# AT32UC3C2128C device description
Architecture: AVR32_UC3; Family: AVR UC3
Registers are 32-bit, read-write, reset 0x0 unless marked. A register's access mark holds for its fields unless they carry their own. Offsets are from the block's base; [hi:lo] are bit positions; lines under a group give offsets from that group; {n}, {i} and the like mark numbered series; 'fields as' and 'values as' point back to an identical list.

## PWM — Pulse Width Modulation Controller
Instances: PWM 0xffff4c00
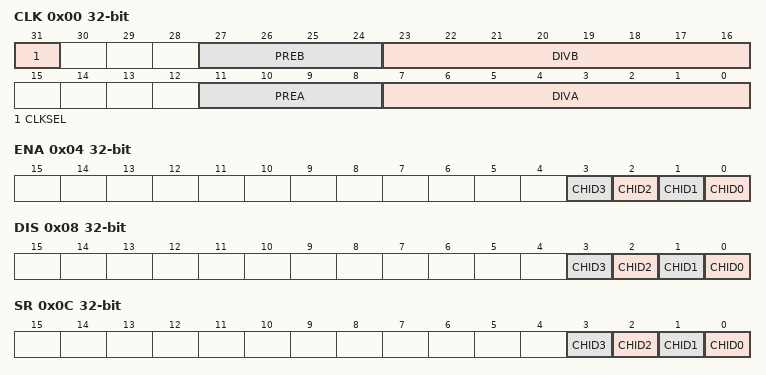
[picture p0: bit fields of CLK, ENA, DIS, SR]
0x00 CLK — PWM Clock Register
  [31] CLKSEL — Clock select
  [27:24] PREB
    0=CCK; 1=CCK_DIV_2; 2=CCK_DIV_4; 3=CCK_DIV_8; 4=CCK_DIV_16; 5=CCK_DIV_32; 6=CCK_DIV_64; 7=CCK_DIV_128; 8=CCK_DIV_256; 9=CCK_DIV_512; 10=CCK_DIV_1024
  [23:16] DIVB — CLKB divide factor
    0=CLK_OFF; 1=CLK_SEL_PREB
  [11:8] PREA
    values as PREB
  [7:0] DIVA — CLKA divide factor
    0=CLK_OFF; 1=CLK_SEL_PREA
0x04 ENA wo reset not defined — PWM Enable Register
  [n] CHID{n} (n=0..3) — Channel ID {n}
0x08 DIS wo reset not defined — PWM Disable Register
  [n] CHID{n} (n=0..3) — Channel ID {n}
0x0C SR ro — PWM Status Register
  [n] CHID{n} (n=0..3) — Channel ID {n}
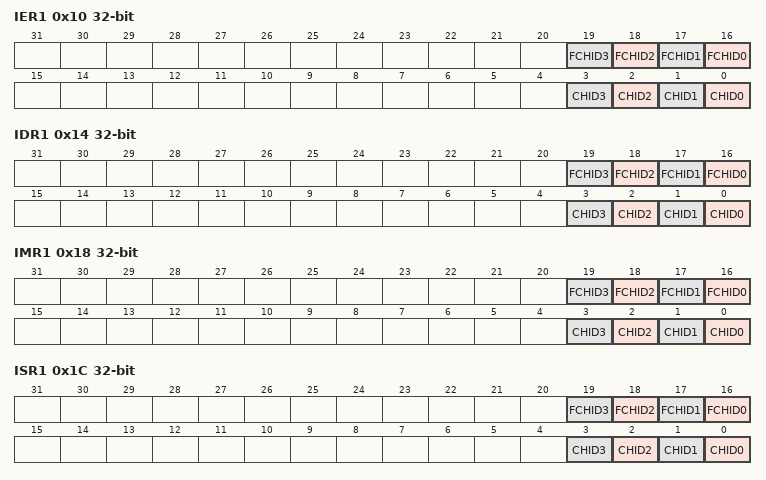
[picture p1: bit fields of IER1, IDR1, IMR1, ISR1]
0x10 IER1 wo reset not defined — PWM Interrupt Enable Register 1
  [n+16] FCHID{n} (n=0..3) — Fault Event on Channel {n} Interrupt Enable
  [n] CHID{n} (n=0..3) — Counter Event on Channel {n} Interrupt Enable
0x14 IDR1 wo reset not defined — PWM Interrupt Disable Register 1
  [n+16] FCHID{n} (n=0..3) — Fault Event on Channel {n} Interrupt Disable
  [n] CHID{n} (n=0..3) — Counter Event on Channel {n} Interrupt Disable
0x18 IMR1 ro — PWM Interrupt Mask Register 1
  [n+16] FCHID{n} (n=0..3) — Fault Event on Channel {n} Interrupt Mask
  [n] CHID{n} (n=0..3) — Counter Event on Channel {n} Interrupt Mask
0x1C ISR1 ro — PWM Interrupt Status Register 1
  [n+16] FCHID{n} (n=0..3) — Fault Event on Channel {n}
  [n] CHID{n} (n=0..3) — Counter Event on Channel {n}
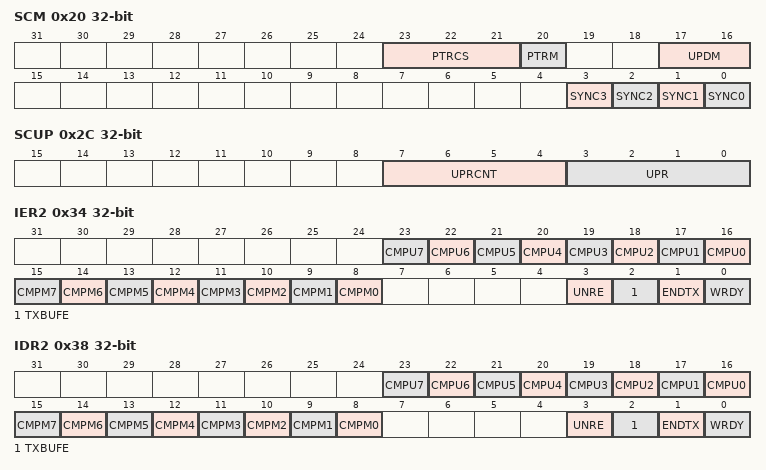
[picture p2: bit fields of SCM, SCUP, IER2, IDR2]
0x20 SCM — PWM Synch Channels Mode Register
  [23:21] PTRCS — PDC Transfer Request Comparison Selection
  [20] PTRM — PDC Transfer Request Mode
    0=PER; 1=CMP
  [17:16] UPDM — Synchronized Channels Update Mode
  [n] SYNC{n} (n=0..3) — Synchronized channel {n}
0x24 PDCDATA
0x28 SCUC — PWM Sync Channels Update Control Register
  [0] UPDULOCK — Synchronous Channels Update Unlock
0x2C SCUP — PWM Sync Channels Update Period Value Register
  [7:4] UPRCNT — Update Period Counter
  [3:0] UPR — Update Period
0x30 SCUPUPD wo — PWM Sync Channels Update Period Value Update Register
  [15:0] UPRUPD — Update Period Update
0x34 IER2 wo reset not defined — PWM Interrupt Enable Register 2
  [n+16] CMPU{n} (n=0..7) — Comparison {n} Update Interrupt Enable
  [n+8] CMPM{n} (n=0..7) — Comparison {n} Match Interrupt Enable
  [3] UNRE — Synchronous Channels Update Underrun Error Interrupt Enable
  [2] TXBUFE — PDC TX Buffer Empty Interrupt Enable
  [1] ENDTX — PDC End of TX Buffer Interrupt Enable
  [0] WRDY — Write Ready for Synchronous Channels Update Interrupt Enable
0x38 IDR2 wo reset not defined — PWM Interrupt Disable Register 2
  [n+16] CMPU{n} (n=0..7) — Comparison {n} Update Interrupt Disable
  [n+8] CMPM{n} (n=0..7) — Comparison {n} Match Interrupt Disable
  [3] UNRE — Synchronous Channels Update Underrun Error Interrupt Disable
  [2] TXBUFE — PDC TX Buffer Empty Interrupt Disable
  [1] ENDTX — PDC End of TX Buffer Interrupt Disable
  [0] WRDY — Write Ready for Synchronous Channels Update Interrupt Disable
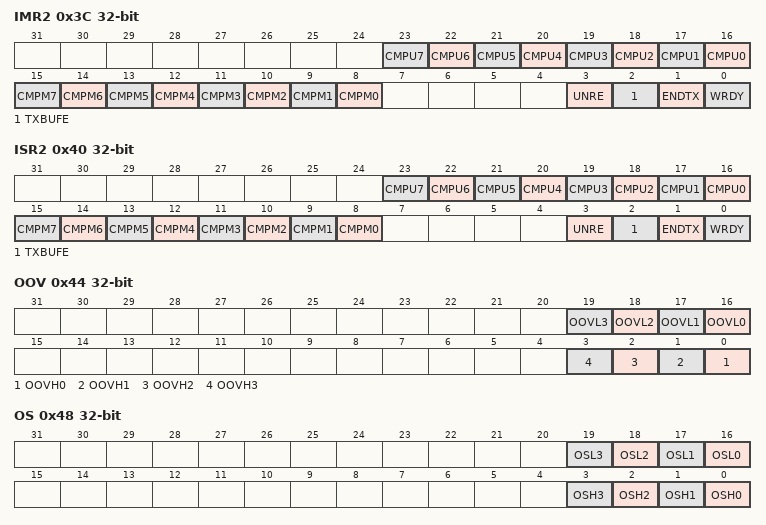
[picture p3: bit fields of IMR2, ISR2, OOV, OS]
0x3C IMR2 ro — PWM Interrupt Mask Register 2
  [n+16] CMPU{n} (n=0..7) — Comparison {n} Update Interrupt Mask
  [n+8] CMPM{n} (n=0..7) — Comparison {n} Match Interrupt Mask
  [3] UNRE — Synchronous Channels Update Underrun Error Interrupt Mask
  [2] TXBUFE — PDC TX Buffer Empty Interrupt Mask
  [1] ENDTX — PDC End of TX Buffer Interrupt Mask
  [0] WRDY — Write Ready for Synchronous Channels Update Interrupt Mask
0x40 ISR2 ro — PWM Interrupt Satus Register 2
  [n+16] CMPU{n} (n=0..7) — Comparison {n} Update
    0=NO; 1=YES
  [n+8] CMPM{n} (n=0..7) — Comparison {n} Match
    0=NO; 1=YES
  [3] UNRE — Synchronous Channels Update Underrun Error Interrupt Status
  [2] TXBUFE — PDC TX Buffer Empty Interrupt Status
  [1] ENDTX — PDC End of TX Buffer Interrupt Status
  [0] WRDY — Write Ready for Synchronous Channels Update Interrupt Status
0x44 OOV — PWM Output Override Value
  [n+16] OOVL{n} (n=0..3) — Output Override Value for PWML Output of the Channel {n}
  [n] OOVH{n} (n=0..3) — Output Override Value for PWMH Output of the Channel {n}
0x48 OS — PWM Output Selection Register
  [n+16] OSL{n} (n=0..3) — Output Selection for PWML Output of the Channel {n}
  [n] OSH{n} (n=0..3) — Output Selection for PWMH Output of the Channel {n}
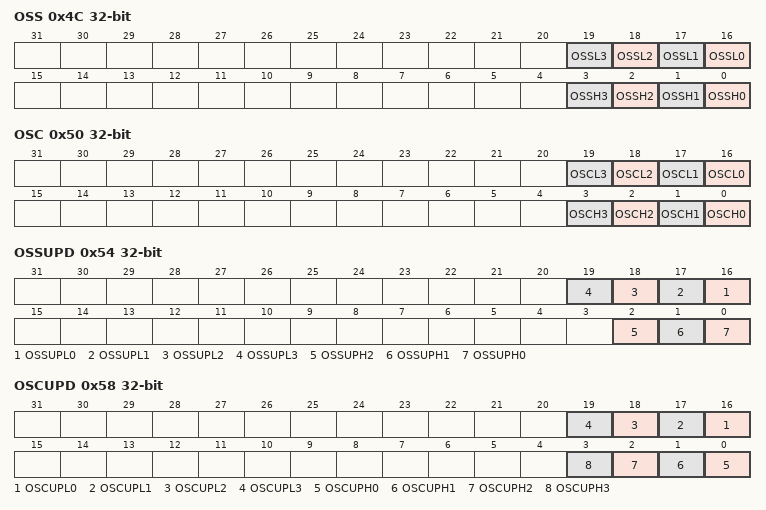
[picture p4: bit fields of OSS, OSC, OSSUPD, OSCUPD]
0x4C OSS wo reset not defined — PWM Output Selection Set Register
  [n+16] OSSL{n} (n=0..3) — Output Selection Set for PWML Output of the Channel {n}
  [n] OSSH{n} (n=0..3) — Output Selection Set for PWMH Output of the Channel {n}
0x50 OSC wo reset not defined — PWM Output Selection Clear Register
  [n+16] OSCL{n} (n=0..3) — Output Selection Clear for PWML Output of the Channel {n}
  [n] OSCH{n} (n=0..3) — Output Selection Clear for PWMH Output of the Channel {n}
0x54 OSSUPD wo reset not defined — PWM Output Selection Set Update Register
  [n+16] OSSUPL{n} (n=0..3) — Output Selection Set Update for PWML Output of the Channel {n}
  [2] OSSUPH2 — Output Selection Set Update for PWMH Output of the Channel 2
  [1] OSSUPH1 — Output Selection Set Update for PWMH Output of the Channel 1
  [0] OSSUPH0 — Output Selection Set Update for PWMH Output of the Channel 0
0x58 OSCUPD wo reset not defined — PWM Output Selection Clear Update Register
  [n+16] OSCUPL{n} (n=0..3) — Output Selection Clear Update for PWML Output of the Channel {n}
  [n] OSCUPH{n} (n=0..3) — Output Selection Clear Update for PWMH Output of the Channel {n}
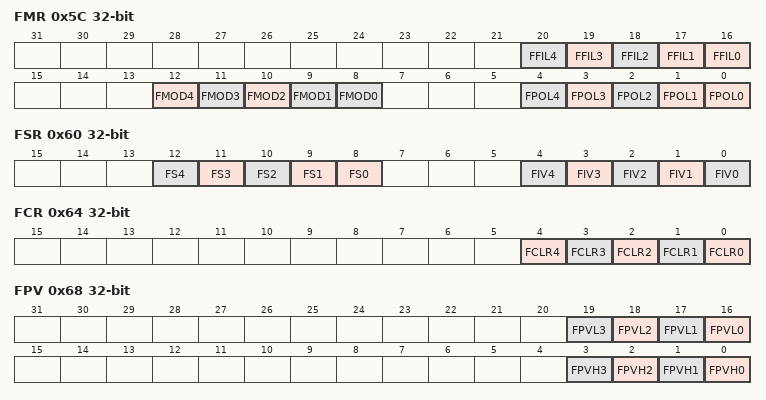
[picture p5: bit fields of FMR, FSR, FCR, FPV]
0x5C FMR — PWM Fault Mode Register
  [n+16] FFIL{n} (n=1..4) — Fault {n} Filtering
  [16] FFIL0 — Fault 0 Filtering
    0=NO; 1=YES
  [n+8] FMOD{n} (n=1..4) — Fault {n} Activation Mode
  [8] FMOD0 — Fault 0 Activation Mode
    0=LEV; 1=CLR
  [n] FPOL{n} (n=1..4) — Fault {n} Polarity
  [0] FPOL0 — Fault 0 Polarity
    0=LO; 1=HI
0x60 FSR ro — PWM Fault Status Register
  [n+8] FS{n} (n=1..4) — Fault {n} Status
  [8] FS0 — Fault 0 Status
    0=NO; 1=YES
  [n] FIV{n} (n=0..4) — Fault Input {n} Value
0x64 FCR wo reset not defined — PWM Fault Clear Register
  [n] FCLR{n} (n=0..4) — Fault {n} Clear
0x68 FPV — PWM Fault Protection Value Register
  [n+16] FPVL{n} (n=0..3) — Fault Protection Value for PWML output on channel {n}
  [n] FPVH{n} (n=0..3) — Fault Protection Value for PWMH output on channel {n}
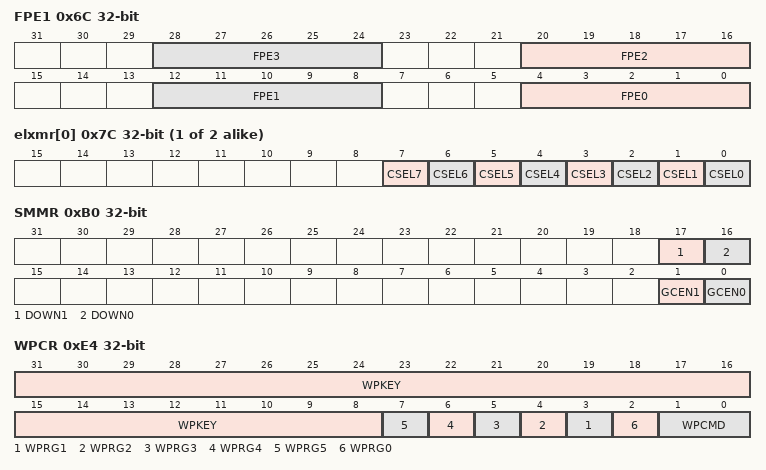
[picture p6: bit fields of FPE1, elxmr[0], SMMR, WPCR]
0x6C FPE1 — PWM Fault Protection Enable Register 1
  [8n+4:8n] FPE{n} (n=0..3) — Fault Protection Enables for PWM Channel {n}
{0x7C+4i} elxmr[{i}] (i=0..1) access not given
  [n] CSEL{n} (n=1..7) — Comparison {n} Selection
  [0] CSEL0 — Comparison 0 Selection
    0=NO; 1=YES
0xB0 SMMR — PWM Stepper Motor Mode
  [17] DOWN1 — 0:Up counter/1:Down counter, channel 1
  [16] DOWN0 — 0:Up counter/1:Down counter, channel 0
  [1] GCEN1 — Enable gray count on PWML[2], PWMH[2], PWML[3], PWMH[3]
  [0] GCEN0 — Enable gray count on PWML[0], PWMH[0], PWML[1], PWMH[1]
0xE4 WPCR wo reset not defined — PWM Write Protect Control Register
  [31:8] WPKEY — Write Protect Key
    0x50574D=KEY
  [n+2] WPRG{n} (n=1..5) — Write Protect Register Group {n}
  [2] WPRG0 — Write Protect Register Group 0
    0=NO; 1=YES
  [1:0] WPCMD — Write Protect Command
    0=SWDIS; 1=SWENA; 2=HWENA
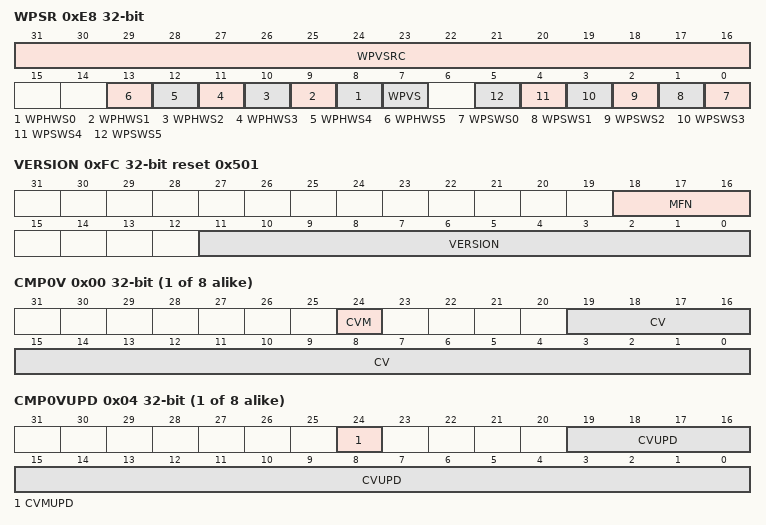
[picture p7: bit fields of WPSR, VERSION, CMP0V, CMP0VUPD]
0xE8 WPSR ro — PWM Write Protect Status Register
  [31:16] WPVSRC — Write Protect Violation Source
  [n+8] WPHWS{n} (n=0..5) — Group {n} Write Protect Hardware Status
    0=NO; 1=YES
  [7] WPVS — Write Protect Violation Status
  [n] WPSWS{n} (n=0..5) — Group {n} Write Protect Software Status
    0=NO; 1=YES
0xFC VERSION ro reset 0x501 — PWM Version Register
  [18:16] MFN, [11:0] VERSION
0x108 TPR — PDC Pointer Register
0x10C TCR — PDC Count Register
0x118 TNPR — PDC Next Pointer Register
0x11C TNCR — PDC Next Count Register
0x120 PTCR — PDC Transfer Control Register
0x124 PTSR — PDC Transfer Status Register
{0x130+0x10*i} comp[{i}] (i=0..7) group
  0x00 CMP0V — PWM Comparison 0 Value Register
    [24] CVM — Comparison 0 Value Mode
      0=INC; 1=DEC
    [19:0] CV — Comparison 0 Value
  0x04 CMP0VUPD wo — PWM Comparison 0 Value Update Register
    [24] CVMUPD — Comparison 0 Value Mode Update
    [19:0] CVUPD — Comparison 0 Value Update
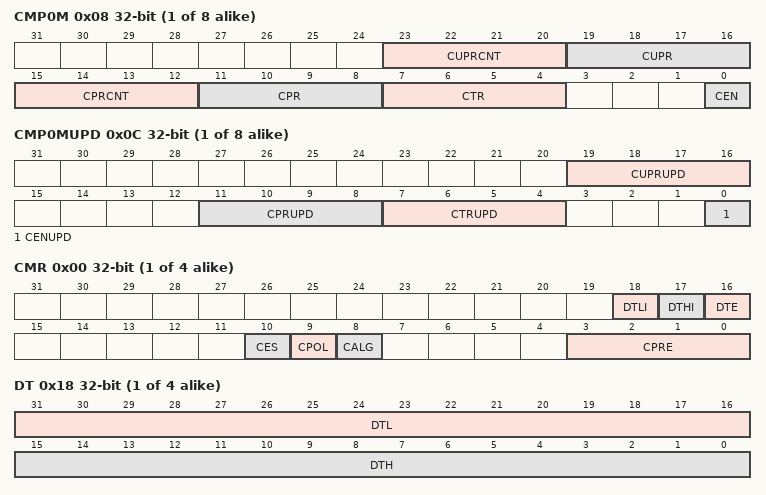
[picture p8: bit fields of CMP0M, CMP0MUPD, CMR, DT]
  0x08 CMP0M — PWM Comparison 0 Mode Register
    [23:20] CUPRCNT — Comparison 0 Update Period Counter
    [19:16] CUPR — Comparison 0 Update Period
    [15:12] CPRCNT — Comparison 0 Period Counter
    [11:8] CPR — Comparison 0 Period
    [7:4] CTR — Comparison 0 Trigger
    [0] CEN — Comparison 0 Enable
      0=NO; 1=YES
  0x0C CMP0MUPD wo — PWM Comparison 0 Mode Update Register
    [19:16] CUPRUPD — Comparison 0 Update Period Update
    [11:8] CPRUPD — Comparison 0 Period Update
    [7:4] CTRUPD — Comparison 0 Trigger Update
    [0] CENUPD — Comparison 0 Enable Update
{0x200+0x20*i} channel[{i}] (i=0..3) group
  0x00 CMR — PWM Channel Mode Register 0
    [18] DTLI — Dead Time PWMLx Output Inverted
    [17] DTHI — Dead Time PWMHx Output Inverted
    [16] DTE — Dead Time Generator Enable
    [10] CES — Counter Event Selection
    [9] CPOL — Channel Polarity
    [8] CALG — Channel Alignment
    [3:0] CPRE — Channel Prescaler
      0=CCK; 1=CCK_DIV_2; 2=CCK_DIV_4; 3=CCK_DIV_8; 4=CCK_DIV_16; 5=CCK_DIV_32; 6=CCK_DIV_64; 7=CCK_DIV_128; 8=CCK_DIV_256; 9=CCK_DIV_512; 10=CCK_DIV_1024; 11=CLKA; 12=CLKB
  0x04 CDTY — PWM Channel Duty Cycle Register 0
    [19:0] CDTY — Channel Duty Cycle
  0x08 CDTYUPD wo reset not defined — PWM Channel Duty Cycle Update Register 0
    [19:0] CDTYUPD — Channel Duty Cycle Update
  0x0C CPRD — PWM Channel Period Register 0
    [19:0] CPRD — Channel Period
  0x10 CPRDUPD wo reset not defined — PWM Channel Period Update Register 0
    [19:0] CPRDUPD — Channel Period Update
  0x14 CCNT ro — PWM Channel Counter Register 0
    [19:0] CNT — Channel Counter Register
  0x18 DT — PWM Dead Time Register 0
    [31:16] DTL — Dead Time Value for PWMLx Output
    [15:0] DTH — Dead Time Value for PWMHx Output
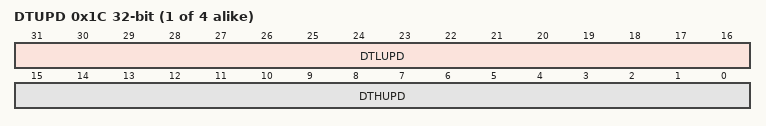
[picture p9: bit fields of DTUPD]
  0x1C DTUPD wo reset not defined — PWM Dead Time Update Register 0
    [31:16] DTLUPD — Dead Time Value Update for PWMHx Output
    [15:0] DTHUPD — Dead Time Value Update for PWMLx Output
